# AC7840x register map
Vendor: AutoChips; Series: AC78; File version: 1.0
CPU: CM4 r0p1, little endian, MPU, FPU, VTOR, 4 interrupt priority bits
Registers are 32-bit, read-write, reset 0x0 unless marked. A register's access mark holds for its fields unless they carry their own. Offsets are from the block's base; [hi:lo] are bit positions; {n}, {i} and the like mark numbered series; 'fields as' and 'values as' point back to an identical list.

## PORTA — Pin Control and Interrupts
Base 0x40085200
Same registers: PORTB 0x40085300, PORTC 0x40085400, PORTD 0x40085500, PORTE 0x40085600
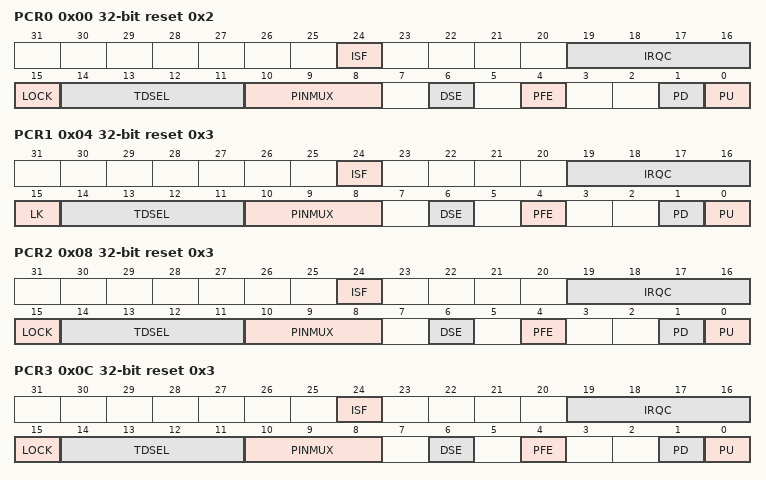
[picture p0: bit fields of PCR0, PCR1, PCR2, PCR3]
0x00 PCR0 reset 0x2 — Pin Control Register n
  [24] ISF — Interrupt Status Flag
    0=Configured interrupt is not detected; 1=Configured interrupt is detected. If the pin is configured to generate a DMA request, then the corresponding flag will be cleared automatically at the completion of the requested DMA transfer. Otherwise, the flag remains set until a logic 1 is written to the flag. If the pin is configured for a level sensitive interrupt and the pin remains asserted, then the flag is set again immediately after it is cleared.
  [19:16] IRQC — Interrupt Configuration
    0=Interrupt Status Flag (ISF) is disabled; 1=ISF flag and DMA request on rising edge; 2=ISF flag and DMA request on falling edge; 3=ISF flag and DMA request on either edge; 8=ISF flag and Interrupt when logic 0; 9=ISF flag and Interrupt on rising-edge; 10=ISF flag and Interrupt on falling-edge; 11=ISF flag and Interrupt on either edge; 12=ISF flag and Interrupt when logic 1
  [15] LOCK
    0=Pin Control Register fields [15:0] are not locked; 1=Pin Control Register fields [15:0] are locked and cannot be updated until the next system reset
  [14:11] TDSEL — TX duty selection
    5=WHEN VDDIO IS 2.5~4.5V, SELECT; 15=WHEN VDDIO IS 4.5~5.5V, SELECT
  [10:8] PINMUX — Pin Mux Control
    0=Pin disabled (Alternative 0) (analog); 1=Alternative 1 (GPIO); {v}=Alternative {v} (chip-specific) (v=2..7)
  [6] DSE — Drive Strength Select
    0=Low drive strength(5mA) is configured on the corresponding pin, if pin is configured as a digital output; 1=High drive strength(20mA) is configured on the corresponding pin, if pin is configured as a digital output
  [4] PFE — Passive Filter Enable
    0=Passive input filter is disabled on the corresponding pin; 1=Passive input filter is enabled on the corresponding pin, if the pin is configured as a digital input
  [1] PD — Pull Down Enable
    0=Internal pulldown resistor is not enabled on the corresponding pin; 1=Internal pulldown resistor is enabled on the corresponding pin, if the pin is configured as a digital input
  [0] PU — Pull Up Enable
    0=Internal pullup resistor is disabled on the corresponding pin; 1=Internal pullup resistor is enabled on the corresponding pin
0x04 PCR1 reset 0x3 — Pin Control Register n
  [24] ISF — Interrupt Status Flag
    values as PCR0.ISF
  [19:16] IRQC — Interrupt Configuration
    values as PCR0.IRQC
  [15] LK — Lock Register
    values as PCR0.LOCK
  [14:11] TDSEL — TX duty selection
    values as PCR0.TDSEL
  [10:8] PINMUX — Pin Mux Control
    values as PCR0.PINMUX
  [6] DSE — Drive Strength Select
    values as PCR0.DSE
  [4] PFE — Passive Filter Enable
    values as PCR0.PFE
  [1] PD — Pull Down Enable
    values as PCR0.PD
  [0] PU — Pull Up Enable
    values as PCR0.PU
0x08 PCR2 reset 0x3 — Pin Control Register n
  fields as PCR0
0x0C PCR3 reset 0x3 — Pin Control Register n
  fields as PCR0
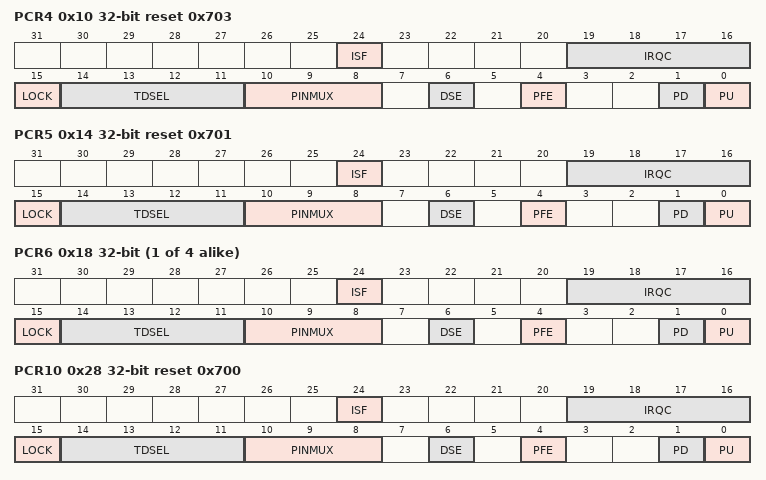
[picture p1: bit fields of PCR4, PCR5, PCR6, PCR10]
0x10 PCR4 reset 0x703 — Pin Control Register n
  fields as PCR0
0x14 PCR5 reset 0x701 — Pin Control Register n
  fields as PCR0
{0x0+4i} PCR{i} (i=6..9) — Pin Control Register n
  fields as PCR0
0x28 PCR10 reset 0x700 — Pin Control Register n
  fields as PCR0
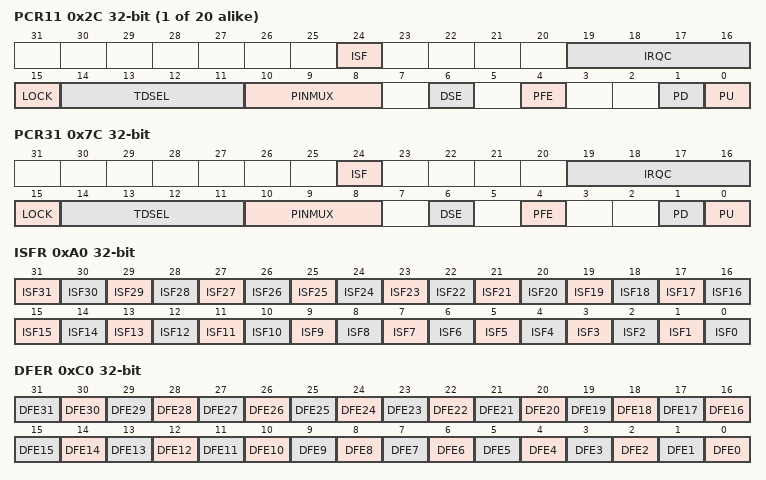
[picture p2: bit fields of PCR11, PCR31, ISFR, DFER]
{0x0+4i} PCR{i} (i=11..30) — Pin Control Register n
  fields as PCR0
0x7C PCR31 — Pin Control Register n
  [24] ISF — Interrupt Status Flag
    values as PCR0.ISF
  [19:16] IRQC — Interrupt Configuration
    values as PCR0.IRQC
  [15] LOCK
    values as PCR0.LOCK
  [14:11] TDSEL — TX duty selection
    5=When VDDIO is 2.5~4.5V, select; 15=WHEN VDDIO IS 4.5~5.5V, SELECT
  [10:8] PINMUX — Pin Mux Control
    values as PCR0.PINMUX
  [6] DSE — Drive Strength Select
    values as PCR0.DSE
  [4] PFE — Passive Filter Enable
    values as PCR0.PFE
  [1] PD — Pull Down Enable
    values as PCR0.PD
  [0] PU — Pull Up Enable
    values as PCR0.PU
0xA0 ISFR — Interrupt Status Flag Register
  [all] fields
    values as PCR0.ISF
  [n] ISF{n} (n=1..31) — Port output data, bit {n}
  [0] ISF0 — Interrupt Status Flag
0xC0 DFER — Digital Filter Enable Register
  [all] fields
    0=Digital filter is disabled on the corresponding pin and output of the digital filter is reset to zero; 1=Digital filter is enabled on the corresponding pin, if the pin is configured as a digital input
  [n] DFE{n} (n=0..31) — Digital Filter Enable
0xC4 DFCR — Digital Filter Clock Register
  [0] CS — Clock Source
    0=Digital filters are clocked by the bus clock; 1=Digital filters are clocked by the LPO clock
0xC8 DFWR — Digital Filter Width Register
  [4:0] FILT — Filter Length
